# RA4M1 register map
Vendor: Renesas Electronics Corporation; Series: RA4; File version: 1.2
CPU: CM4 r0p1, little endian, MPU, FPU, VTOR, 4 interrupt priority bits
Registers are 8-bit, read-write, reset 0x0 unless marked. A register's access mark holds for its fields unless they carry their own. Offsets are from the block's base; [hi:lo] are bit positions.

## TSN — Temperature Sensor
Base 0x407EC000
0x228 TSCDRL ro reset not defined — Temperature Sensor Calibration Data Register L
  [7:0] TSCDRL — The calibration data stores the lower 8 bits of the converted value.
0x229 TSCDRH ro reset not defined — Temperature Sensor Calibration Data Register H
  [7:0] TSCDRH — The calibration data stores the higher 8 bits of the converted value.

## WDT — Watchdog Timer
Base 0x40044200
0x00 WDTRR reset 0xFF — WDT Refresh Register
  [7:0] WDTRR — WDTRR is an 8-bit register that refreshes the down-counter of the WDT.
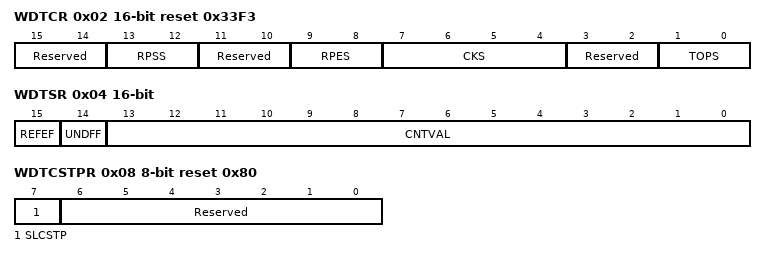
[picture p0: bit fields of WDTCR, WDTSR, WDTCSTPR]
0x02 WDTCR 16-bit reset 0x33F3 — WDT Control Register
  [15:14] Reserved — These bits are read as 00. The write value should be 00.
  [13:12] RPSS — Window Start Position Selection
    0=25 percent; 1=50 percent; 2=75 percent; 3=100 percent (window start position is not specified)
  [11:10] Reserved — These bits are read as 00. The write value should be 00.
  [9:8] RPES — Window End Position Selection
    0=75 percent; 1=50 percent; 2=25 percent; 3=0 percent (window end position is not specified)
  [7:4] CKS — Clock Division Ratio Selection
    1=PCLK/4; 4=PCLK/64; 15=PCLK/128; 6=PCLK/512; 7=PCLK/2048; 8=PCLK/8192; other=others (setting prohibited)
  [3:2] Reserved — These bits are read as 00. The write value should be 00.
  [1:0] TOPS — Timeout Period Selection
    0=1,024 cycles (03FFh); 1=4,096 cycles (0FFFh); 2=8,192 cycles (1FFFh); 3=16,384 cycles (3FFFh)
0x04 WDTSR 16-bit — WDT Status Register
  [15] REFEF write-0-clears read-modifies — Refresh Error Flag
    0=No refresh error occurred; 1=Refresh error occurred
  [14] UNDFF write-0-clears read-modifies — Underflow Flag
    0=No underflow occurred; 1=Underflow occurred
  [13:0] CNTVAL ro — Down-Counter Value Value counted by the down-counter
0x06 WDTRCR reset 0x80 — WDT Reset Control Register
  [7] RSTIRQS — Reset Interrupt Request Selection
    0=Non-maskable interrupt request or interrupt request output is enabled; 1=Reset output is enabled
0x08 WDTCSTPR reset 0x80 — WDT Count Stop Control Register
  [7] SLCSTP — Sleep-Mode Count Stop Control
    0=Count stop is disabled; 1=Count is stopped at a transition to sleep mode
  [6:0] Reserved — These bits are read as 0000000. The write value should be 0000000.

## GPT_OPS — Output Phase Switching Controller
Base 0x40078FF0
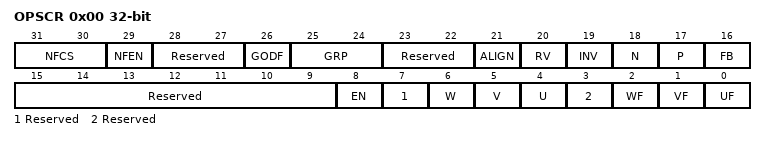
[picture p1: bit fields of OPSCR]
0x00 OPSCR 32-bit — Output Phase Switching Control Register
  [31:30] NFCS — External Input Noise Filter Clock selection Noise filter sampling clock setting of the external input.
    0=PCLK/1; 1=PCLK/4; 2=PCLK/16; 3=PCLK/64
  [29] NFEN — External Input Noise Filter Enable
    0=Do not use a noise filter to the external input; 1=Use a noise filter to the external input
  [28:27] Reserved — These bits are read as 00. The write value should be 00.
  [26] GODF — Group output disable function
    0=This bit function is ignored; 1=Group disable will clear OPSCR.EN Bit
  [25:24] GRP — Output disabled source selection
    0=Select Group A output disable source; 1=Select Group B output disable source; other=others (Setting prohibited)
  [23:22] Reserved — These bits are read as 00. The write value should be 00.
  [21] ALIGN — Input phase alignment
    0=Input phase is aligned to PCLK; 1=Input phase is aligned PWM
  [20] RV — Output phase rotation direction reversal
    0=U/V/W-Phase output; 1=Output to reverse the V / W-phase
  [19] INV — Invert-Phase Output Control
    0=Positive Logic (Active High)output; 1=Negative Logic (Active Low)output
  [18] N — Negative-Phase Output (N) Control
    0=Level signal output; 1=PWM signal output (PWM of GPT0)
  [17] P — Positive-Phase Output (P) Control
    0=Level signal output; 1=PWM signal output (PWM of GPT0)
  [16] FB — External Feedback Signal Enable This bit selects the input phase from the software settings and external input.
    0=Select the external input; 1=Select the soft setting(OPSCR.UF, VF, WF)
  [15:9] Reserved — These bits are read as 0000000. The write value should be 0000000.
  [8] EN — Enable-Phase Output Control
    0=Not Output(Hi-Z external terminals); 1=Output
  [7] Reserved — This bit is read as 0. The write value should be 0.
  [6] W ro — Input W-Phase Monitor This bit monitors the state of the input phase. OPSCR.FB=0:External input monitoring by PCLK OPSCR.FB=1:Software settings (UF/VF/WF)
  [5] V ro — Input V-Phase Monitor This bit monitors the state of the input phase. OPSCR.FB=0:External input monitoring by PCLK OPSCR.FB=1:Software settings (UF/VF/WF)
  [4] U ro — Input U-Phase Monitor This bit monitors the state of the input phase. OPSCR.FB=0:External input monitoring by PCLK OPSCR.FB=1:Software settings (UF/VF/WF)
  [3] Reserved — This bit is read as 0. The write value should be 0.
  [2] WF — Input Phase Soft Setting UF This bit sets the input phase by the software settings. This bit setting is valid when the OPSCR.FB bit = 1.
  [1] VF — Input Phase Soft Setting VF This bit sets the input phase by the software settings. This bit setting is valid when the OPSCR.FB bit = 1.
  [0] UF — Input Phase Soft Setting WF This bit sets the input phase by the software settings. This bit setting is valid when the OPSCR.FB bit = 1.
